VERSION ""

NS_ :

BS_:

BU_: Vector__XXX ECM_MOTOR ECU_eClutch PUMP CCU
VAL_TABLE_ OverVoltage 3 "N/A" 2 "Invalid" 1 "Active" 0 "Not Active" ;
VAL_TABLE_ MotorMode 3 "N/A" 2 "Running" 1 "Starting" 0 "Stopped" ;
VAL_TABLE_ FailedStart 3 "N/A" 2 "Invalid" 1 "Active" 0 "Not Active" ;
VAL_TABLE_ InputParamOutOfRange 3 "N/A" 2 "Invalid" 1 "Active" 0 "Not Active" ;
VAL_TABLE_ CurrentLimiting 3 "N/A" 2 "Invalid" 1 "Active" 0 "Not Active" ;
VAL_TABLE_ OverCurrent 3 "N/A" 2 "Invalid" 1 "Active" 0 "Not Active" ;
VAL_TABLE_ LowVoltage_MaxPWM 3 "N/A" 2 "Invalid" 1 "Active" 0 "Not Active" ;
VAL_TABLE_ Ramp 3 "Ramp #3" 2 "Ramp #2" 1 "Ramp #1" 0 "Ramp #0" ;
VAL_TABLE_ CommandStatus 62 "Fault" 20 "Stopped" 9 "Starting" 1 "Running" ;
VAL_TABLE_ ModeStatus 3 "Not Available" ;
VAL_TABLE_ Mode 3 "Not Available" 2 "Error" 1 "24V" 0 "12V" ;
VAL_TABLE_ Command 19 "Shutdown" 1 "Run" ;
VAL_TABLE_ CurrentLimit 255 "N/A" 254 "N/A" 253 "N/A" 252 "N/A" 251 "N/A" 250 "Limit to 12A" 249 "Limit to 12A" 248 "Limit to 12A" 247 "Limit to 12A" 246 "Limit to 12A" 245 "Limit to 12A" 244 "Limit to 12A" 243 "Limit to 12A" 242 "Limit to 12A" 241 "Limit to 12A" 240 "Limit to 12A" 239 "Limit to 12A" 238 "Limit to 12A" 237 "Limit to 12A" 236 "Limit to 12A" 235 "Limit to 12A" 234 "Limit to 12A" 233 "Limit to 12A" 232 "Limit to 12A" 231 "Limit to 12A" 230 "Limit to 12A" 229 "Limit to 12A" 228 "Limit to 12A" 227 "Limit to 12A" 226 "Limit to 12A" 225 "Limit to 12A" 224 "Limit to 12A" 223 "Limit to 12A" 222 "Limit to 12A" 221 "Limit to 12A" 220 "Limit to 12A" 219 "Limit to 12A" 218 "Limit to 12A" 217 "Limit to 12A" 216 "Limit to 12A" 215 "Limit to 12A" 214 "Limit to 12A" 213 "Limit to 12A" 212 "Limit to 12A" 211 "Limit to 12A" 210 "Limit to 12A" 209 "Limit to 12A" 208 "Limit to 12A" 207 "Limit to 12A" 206 "Limit to 12A" 205 "Limit to 12A" 204 "Limit to 12A" 203 "Limit to 12A" 202 "Limit to 12A" 201 "Limit to 12A" 200 "Limit to 12A" 199 "Limit to 12A" 198 "Limit to 12A" 197 "Limit to 12A" 196 "Limit to 12A" 195 "Limit to 12A" 194 "Limit to 12A" 193 "Limit to 12A" 192 "Limit to 12A" 191 "Limit to 12A" 190 "Limit to 12A" 189 "Limit to 12A" 188 "Limit to 12A" 187 "Limit to 12A" 186 "Limit to 12A" 185 "Limit to 12A" 184 "Limit to 12A" 183 "Limit to 12A" 182 "Limit to 12A" 181 "Limit to 12A" 180 "Limit to 12A" 179 "Limit to 12A" 178 "Limit to 12A" 177 "Limit to 12A" 176 "Limit to 12A" 175 "Limit to 12A" 174 "Limit to 12A" 173 "Limit to 12A" 172 "Limit to 12A" 171 "Limit to 12A" 170 "Limit to 12A" 169 "Limit to 12A" 168 "Limit to 12A" 167 "Limit to 12A" 166 "Limit to 12A" 165 "Limit to 12A" 164 "Limit to 12A" 163 "Limit to 12A" 162 "Limit to 12A" 161 "Limit to 12A" 160 "Limit to 12A" 159 "Limit to 12A" 158 "Limit to 12A" 157 "Limit to 12A" 156 "Limit to 12A" 155 "Limit to 12A" 154 "Limit to 12A" 153 "Limit to 12A" 152 "Limit to 12A" 151 "Limit to 12A" 150 "Limit to 12A" 149 "Limit to 12A" 148 "Limit to 12A" 147 "Limit to 12A" 146 "Limit to 12A" 145 "Limit to 12A" 144 "Limit to 12A" 143 "Limit to 12A" 142 "Limit to 12A" 141 "Limit to 12A" 140 "Limit to 12A" 139 "Limit to 12A" 138 "Limit to 12A" 137 "Limit to 12A" 136 "Limit to 12A" 135 "Limit to 12A" 134 "Limit to 12A" 133 "Limit to 12A" 132 "Limit to 12A" 131 "Limit to 12A" 130 "Limit to 12A" 129 "Limit to 12A" 128 "Limit to 12A" 127 "Limit to 12A" 126 "Limit to 12A" 125 "Limit to 12A" 124 "Limit to 12A" 123 "Limit to 12A" 122 "Limit to 12A" 121 "Limit to 12A" 120 "Limit to 12A" 119 "Limit to 12A" 118 "Limit to 12A" 117 "Limit to 12A" 116 "Limit to 12A" 115 "Limit to 12A" 114 "Limit to 12A" 113 "Limit to 12A" 112 "Limit to 12A" 111 "Limit to 12A" 110 "Limit to 12A" 109 "Limit to 12A" 108 "Limit to 12A" 107 "Limit to 12A" 106 "Limit to 12A" 105 "Limit to 12A" 104 "Limit to 12A" 103 "Limit to 12A" 102 "Limit to 12A" 101 "Limit to 12A" 100 "Limit to 12A" 99 "Limit to 12A" 98 "Limit to 12A" 97 "Limit to 12A" 96 "Limit to 12A" 95 "Limit to 12A" 94 "Limit to 12A" 93 "Limit to 12A" 92 "Limit to 12A" 91 "Limit to 12A" 90 "Limit to 12A" 89 "Limit to 12A" 88 "Limit to 12A" 87 "Limit to 12A" 86 "Limit to 12A" 85 "Limit to 12A" 84 "Limit to 12A" 83 "Limit to 12A" 82 "Limit to 12A" 81 "Limit to 12A" 80 "Limit to 12A" 79 "Limit to 12A" 78 "Limit to 12A" 77 "Limit to 12A" 76 "Limit to 12A" 75 "Limit to 12A" 74 "Limit to 12A" 73 "Limit to 12A" 72 "Limit to 12A" 71 "Limit to 12A" 70 "Limit to 12A" 69 "Limit to 12A" 68 "Limit to 12A" 67 "Limit to 12A" 66 "Limit to 12A" 65 "Limit to 12A" 64 "Limit to 12A" 63 "Limit to 12A" 62 "Limit to 12A" 61 "Limit to 12A" 60 "Limit to 12A" 59 "Limit to 12A" 58 "Limit to 12A" 57 "Limit to 12A" 56 "Limit to 12A" 55 "Limit to 12A" 54 "Limit to 12A" 53 "Limit to 12A" 52 "Limit to 12A" 51 "Limit to 12A" 50 "Limit to 12A" 49 "Limit to 12A" 48 "Limit to 12A" 47 "Limit to 12A" 46 "Limit to 12A" 45 "Limit to 12A" 44 "Limit to 12A" 43 "Limit to 12A" 42 "Limit to 12A" 41 "Limit to 12A" 40 "Limit to 12A" 39 "Limit to 12A" 38 "Limit to 12A" 37 "Limit to 12A" 36 "Limit to 12A" 35 "Limit to 12A" 34 "Limit to 12A" 33 "Limit to 12A" 32 "Limit to 12A" 31 "Limit to 12A" 30 "Limit to 12A" 29 "Limit to 12A" 28 "Limit to 12A" 27 "Limit to 12A" 26 "Limit to 12A" 25 "Limit to 12A" 24 "Limit to 12A" 23 "Limit to 12A" 22 "Limit to 12A" 21 "Limit to 12A" 20 "Limit to 12A" 19 "Limit to 12A" 18 "Limit to 12A" 17 "Limit to 12A" 16 "Limit to 12A" 15 "Limit to 12A" 14 "Limit to 12A" 13 "Limit to 12A" 12 "Limit to 12A" 11 "Limit to 11A" 10 "Limit to 10 A" 9 "Limit to 9 A" 8 "Limit to 8 A" 7 "Limit to 7 A" 6 "Limit to 6 A" 5 "Limit to 5 A" 4 "Limit to 4 A" 3 "Limit to 3 A" 2 "Limit to 2 A" 1 "Limit to 1 A" 0 "Limit to 7 A" ;

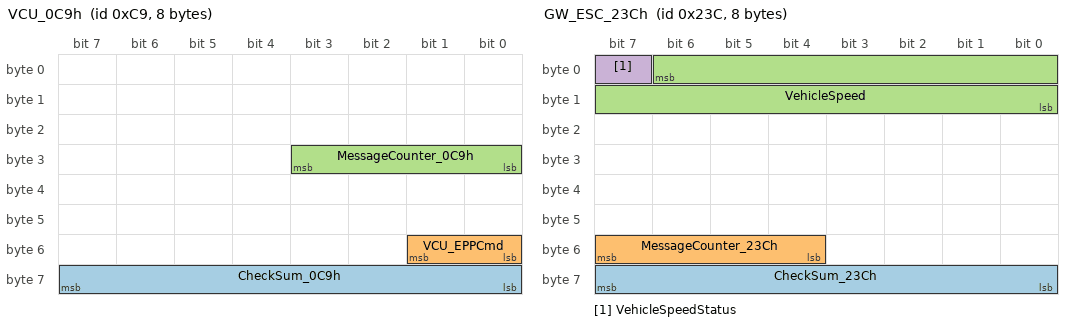
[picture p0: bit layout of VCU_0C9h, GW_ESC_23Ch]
BO_ 201 VCU_0C9h: 8 Vector__XXX
 SG_ CheckSum_0C9h : 63|8@0+ (1,0) [0|255] "" Vector__XXX
 SG_ VCU_EPPCmd : 49|2@0+ (1,0) [0|1] "" Vector__XXX
 SG_ MessageCounter_0C9h : 27|4@0+ (1,0) [0|15] "" Vector__XXX

BO_ 572 GW_ESC_23Ch: 8 Vector__XXX
 SG_ CheckSum_23Ch : 63|8@0+ (1,0) [0|255] "" Vector__XXX
 SG_ MessageCounter_23Ch : 55|4@0+ (1,0) [0|15] "" Vector__XXX
 SG_ VehicleSpeed : 6|15@0+ (0.015625,0) [0|511.984375] "km / h" Vector__XXX
 SG_ VehicleSpeedStatus : 7|1@0+ (1,0) [0|1] "" Vector__XXX

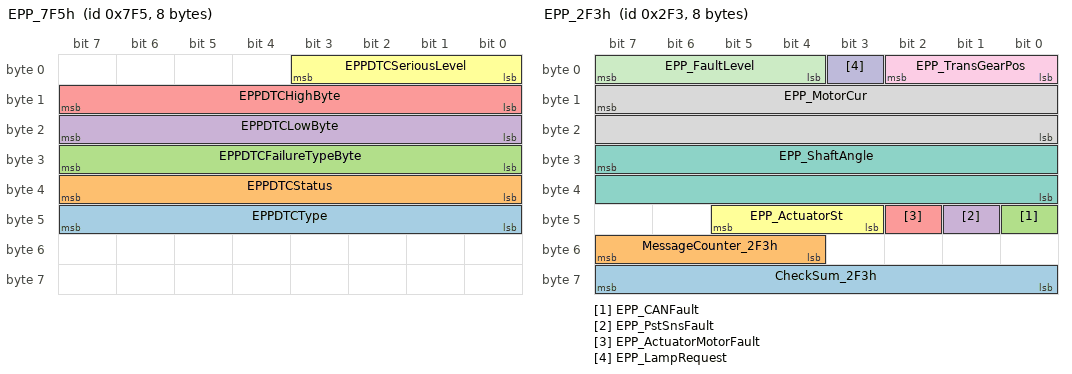
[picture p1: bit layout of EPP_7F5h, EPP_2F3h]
BO_ 2037 EPP_7F5h: 8 Vector__XXX
 SG_ EPPDTCType : 47|8@0+ (1,0) [0|255] "" Vector__XXX
 SG_ EPPDTCStatus : 39|8@0+ (1,0) [0|255] "" Vector__XXX
 SG_ EPPDTCFailureTypeByte : 31|8@0+ (1,0) [0|255] "" Vector__XXX
 SG_ EPPDTCLowByte : 23|8@0+ (1,0) [0|255] "" Vector__XXX
 SG_ EPPDTCHighByte : 15|8@0+ (1,0) [0|255] "" Vector__XXX
 SG_ EPPDTCSeriousLevel : 3|4@0+ (1,0) [0|15] "" Vector__XXX

BO_ 755 EPP_2F3h: 8 Vector__XXX
 SG_ CheckSum_2F3h : 63|8@0+ (1,0) [0|255] "" Vector__XXX
 SG_ MessageCounter_2F3h : 55|4@0+ (1,0) [0|15] "" Vector__XXX
 SG_ EPP_CANFault : 40|1@0+ (1,0) [0|1] "" Vector__XXX
 SG_ EPP_PstSnsFault : 41|1@0+ (1,0) [0|1] "" Vector__XXX
 SG_ EPP_ActuatorMotorFault : 42|1@0+ (1,0) [0|1] "" Vector__XXX
 SG_ EPP_ActuatorSt : 45|3@0+ (1,0) [0|7] "" Vector__XXX
 SG_ EPP_ShaftAngle : 31|16@0+ (0.0030517578125,-100) [-100|99.9969482421875] "Deg" Vector__XXX
 SG_ EPP_MotorCur : 15|16@0+ (0.0030517578125,-100) [-100|99.9969482421875] "A" Vector__XXX
 SG_ EPP_TransGearPos : 2|3@0+ (1,0) [0|7] "" Vector__XXX
 SG_ EPP_LampRequest : 3|1@0+ (1,0) [0|1] "" Vector__XXX
 SG_ EPP_FaultLevel : 7|4@0+ (1,0) [0|15] "" Vector__XXX

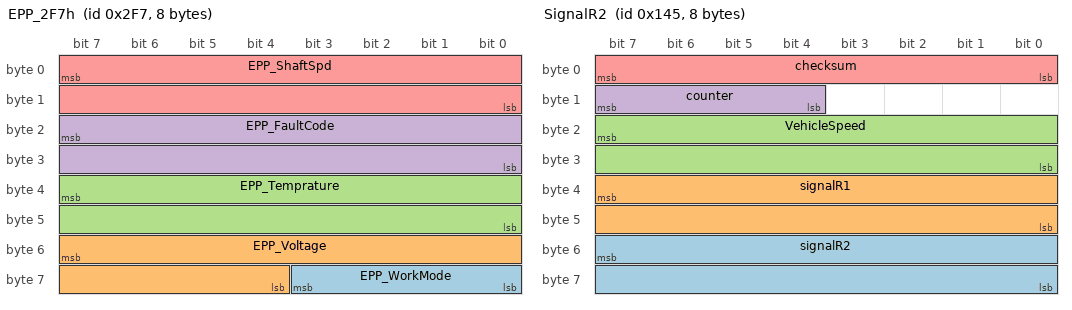
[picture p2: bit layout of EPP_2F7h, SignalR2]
BO_ 759 EPP_2F7h: 8 Vector__XXX
 SG_ EPP_WorkMode : 59|4@0+ (1,0) [0|15] "" Vector__XXX
 SG_ EPP_Voltage : 55|12@0+ (0.0103759765625,0) [0|42.4896] "V" Vector__XXX
 SG_ EPP_Temprature : 39|16@0+ (0.0030517578125,-45) [-45|154.9969] "℃" Vector__XXX
 SG_ EPP_FaultCode : 23|16@0+ (1,0) [0|4095] "" Vector__XXX
 SG_ EPP_ShaftSpd : 7|16@0+ (0.0030517578125,-100) [-100|99.9969482421875] "rpm" Vector__XXX

BO_ 325 SignalR2: 8 ECU_eClutch
 SG_ signalR2 : 55|16@0+ (1,0) [0|65535] ""  ECM_MOTOR
 SG_ signalR1 : 39|16@0+ (1,0) [0|65535] ""  ECM_MOTOR
 SG_ VehicleSpeed : 23|16@0+ (0.015625,0) [0|1023.984375] "km/h"  ECM_MOTOR
 SG_ counter : 15|4@0+ (1,0) [0|15] ""  ECM_MOTOR
 SG_ checksum : 7|8@0+ (1,0) [0|255] ""  ECM_MOTOR

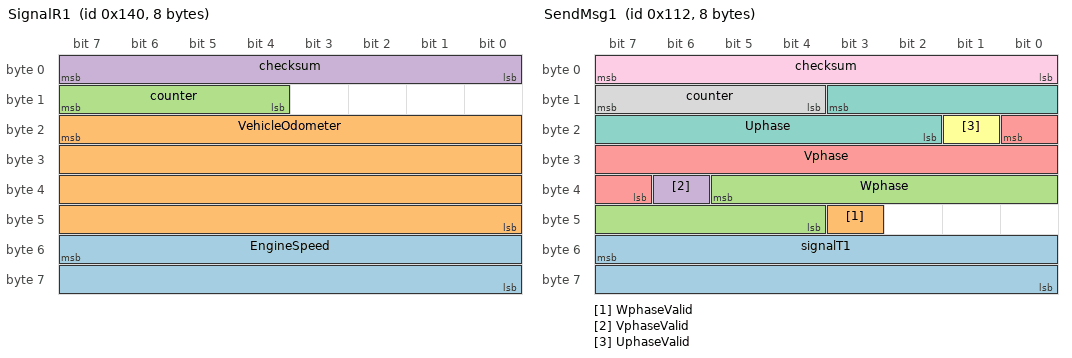
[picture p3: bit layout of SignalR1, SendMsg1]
BO_ 320 SignalR1: 8 ECU_eClutch
 SG_ EngineSpeed : 55|16@0+ (0.25,0) [0|16383.75] "rpm"  ECM_MOTOR
 SG_ VehicleOdometer : 23|32@0+ (0.015625,0) [0|67108863.984375] "km"  ECM_MOTOR
 SG_ counter : 15|4@0+ (1,0) [0|15] ""  ECM_MOTOR
 SG_ checksum : 7|8@0+ (1,0) [0|255] ""  ECM_MOTOR

BO_ 274 SendMsg1: 8 ECM_MOTOR
 SG_ signalT1 : 55|16@0+ (1,0) [0|65535] ""  ECU_eClutch
 SG_ WphaseValid : 43|1@0+ (1,0) [0|1] ""  ECU_eClutch
 SG_ Wphase : 37|10@0+ (0.195,-100) [-100|99.485] ""  ECU_eClutch
 SG_ VphaseValid : 38|1@0+ (1,0) [0|1] ""  ECU_eClutch
 SG_ Vphase : 16|10@0+ (0.195,-100) [-100|99.485] ""  ECU_eClutch
 SG_ UphaseValid : 17|1@0+ (1,0) [0|1] ""  ECU_eClutch
 SG_ Uphase : 11|10@0+ (0.195,-100) [-100|99.485] ""  ECU_eClutch
 SG_ counter : 15|4@0+ (1,0) [0|15] ""  ECU_eClutch
 SG_ checksum : 7|8@0+ (1,0) [0|255] ""  ECU_eClutch

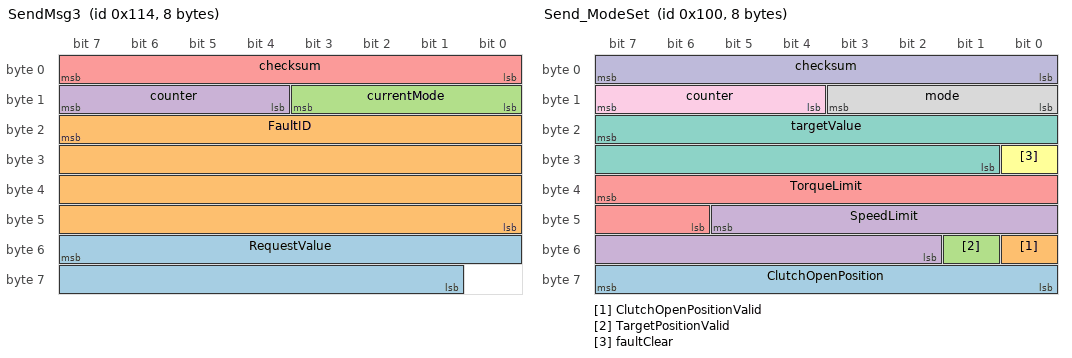
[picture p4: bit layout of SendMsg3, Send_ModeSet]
BO_ 276 SendMsg3: 8 ECM_MOTOR
 SG_ RequestValue : 55|15@0+ (1,0) [0|32767] ""  ECU_eClutch
 SG_ FaultID : 23|32@0+ (1,0) [0|4294967295] ""  ECU_eClutch
 SG_ currentMode : 11|4@0+ (1,0) [0|15] ""  ECU_eClutch
 SG_ counter : 15|4@0+ (1,0) [0|15] ""  ECU_eClutch
 SG_ checksum : 7|8@0+ (1,0) [0|255] ""  ECU_eClutch

BO_ 256 Send_ModeSet: 8 ECU_eClutch
 SG_ ClutchOpenPosition : 63|8@0+ (0.1,0) [0|25.5] "rev"  ECM_MOTOR
 SG_ ClutchOpenPositionValid : 48|1@0+ (1,0) [0|1] ""  ECM_MOTOR
 SG_ TargetPositionValid : 49|1@0+ (1,0) [0|1] ""  ECM_MOTOR
 SG_ SpeedLimit : 45|12@0+ (2.442,0) [0|9999.99] ""  ECM_MOTOR
 SG_ TorqueLimit : 39|10@0+ (0.0977,0) [0|99.9471] ""  ECM_MOTOR
 SG_ faultClear : 24|1@0+ (1,0) [0|1] ""  ECM_MOTOR
 SG_ targetValue : 23|15@0+ (1,0) [0|32767] ""  ECM_MOTOR
 SG_ mode : 11|4@0+ (1,0) [0|15] ""  ECM_MOTOR
 SG_ counter : 15|4@0+ (1,0) [0|15] ""  ECM_MOTOR
 SG_ checksum : 7|8@0+ (1,0) [0|255] ""  ECM_MOTOR

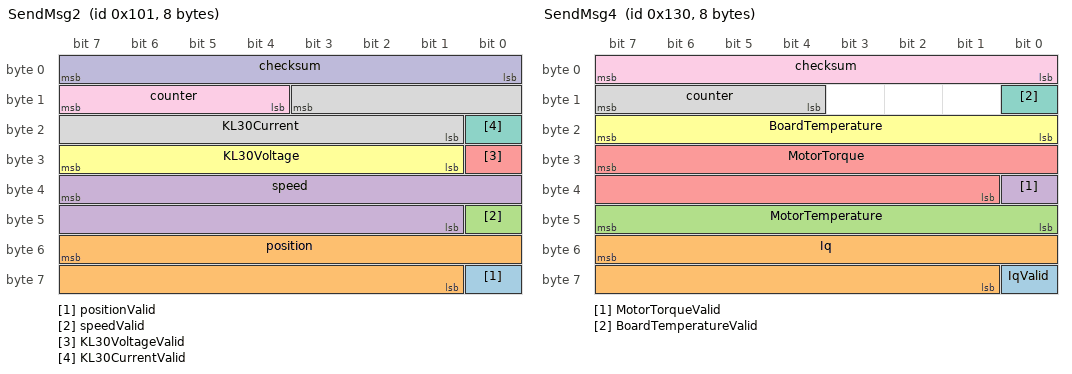
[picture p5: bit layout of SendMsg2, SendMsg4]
BO_ 257 SendMsg2: 8 ECM_MOTOR
 SG_ positionValid : 56|1@0+ (1,0) [0|1] ""  ECU_eClutch
 SG_ position : 55|15@0+ (0.001526,-25) [-25|25.002442] ""  ECU_eClutch
 SG_ speedValid : 40|1@0+ (1,0) [0|1] ""  ECU_eClutch
 SG_ speed : 39|15@0+ (0.6104,-10000) [-10000|10000.9768] ""  ECU_eClutch
 SG_ KL30VoltageValid : 24|1@0+ (1,0) [0|1] ""  ECU_eClutch
 SG_ KL30Voltage : 31|7@0+ (0.237,0) [0|30.099] ""  ECU_eClutch
 SG_ KL30CurrentValid : 16|1@0+ (1,0) [0|1] ""  ECU_eClutch
 SG_ KL30Current : 11|11@0+ (0.0489,0) [0|100.0983] ""  ECU_eClutch
 SG_ counter : 15|4@0+ (1,0) [0|15] ""  ECU_eClutch
 SG_ checksum : 7|8@0+ (1,0) [0|255] ""  ECU_eClutch

BO_ 304 SendMsg4: 8 ECM_MOTOR
 SG_ IqValid : 56|1@0+ (1,0) [0|1] ""  ECU_eClutch
 SG_ Iq : 55|15@0+ (0.01,-160) [-160|167.67] ""  ECU_eClutch
 SG_ MotorTemperature : 47|8@0+ (1,-60) [-60|195] ""  ECU_eClutch
 SG_ MotorTorqueValid : 32|1@0+ (1,0) [0|1] ""  ECU_eClutch
 SG_ MotorTorque : 31|15@0+ (0.0001525,-2) [-2|2.9969675] ""  ECU_eClutch
 SG_ BoardTemperature : 23|8@0+ (1,-60) [-60|195] ""  ECU_eClutch
 SG_ BoardTemperatureValid : 8|1@0+ (1,0) [0|1] ""  ECU_eClutch
 SG_ counter : 15|4@0+ (1,0) [0|15] ""  ECU_eClutch
 SG_ checksum : 7|8@0+ (1,0) [0|255] ""  ECU_eClutch

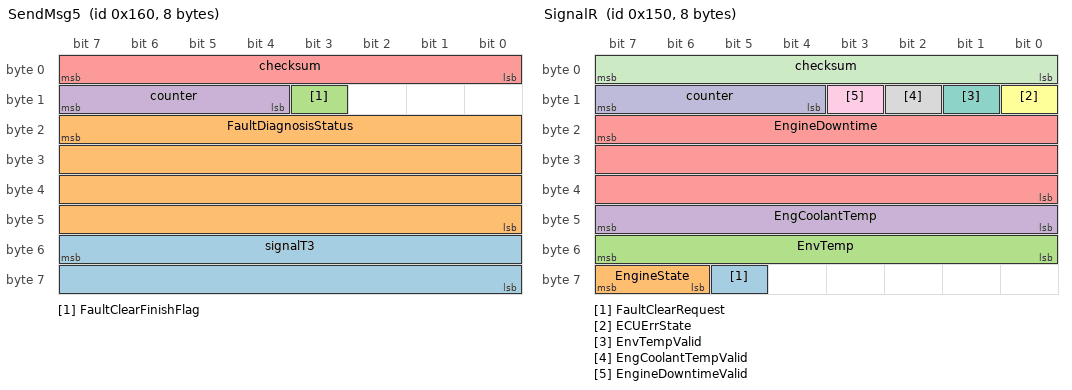
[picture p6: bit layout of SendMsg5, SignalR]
BO_ 352 SendMsg5: 8 ECM_MOTOR
 SG_ signalT3 : 55|16@0+ (1,0) [0|65535] ""  ECU_eClutch
 SG_ FaultDiagnosisStatus : 23|32@0+ (1,0) [0|4294967295] ""  ECU_eClutch
 SG_ FaultClearFinishFlag : 11|1@0+ (1,0) [0|1] ""  ECU_eClutch
 SG_ counter : 15|4@0+ (1,0) [0|15] ""  ECU_eClutch
 SG_ checksum : 7|8@0+ (1,0) [0|255] ""  ECU_eClutch

BO_ 336 SignalR: 8 ECU_eClutch
 SG_ FaultClearRequest : 61|1@0+ (1,0) [0|1] ""  ECM_MOTOR
 SG_ EngineState : 63|2@0+ (1,0) [0|3] ""  ECM_MOTOR
 SG_ EnvTemp : 55|8@0+ (1,-40) [-40|215] "℃"  ECM_MOTOR
 SG_ EngCoolantTemp : 47|8@0+ (1,-40) [-40|215] "℃"  ECM_MOTOR
 SG_ EngineDowntime : 23|24@0+ (1,0) [0|16777215] "s"  ECM_MOTOR
 SG_ ECUErrState : 8|1@0+ (1,0) [0|1] ""  ECM_MOTOR
 SG_ EnvTempValid : 9|1@0+ (1,0) [0|1] ""  ECM_MOTOR
 SG_ EngCoolantTempValid : 10|1@0+ (1,0) [0|1] ""  ECM_MOTOR
 SG_ EngineDowntimeValid : 11|1@0+ (1,0) [0|1] ""  ECM_MOTOR
 SG_ counter : 15|4@0+ (1,0) [0|15] ""  ECM_MOTOR
 SG_ checksum : 7|8@0+ (1,0) [0|255] ""  ECM_MOTOR

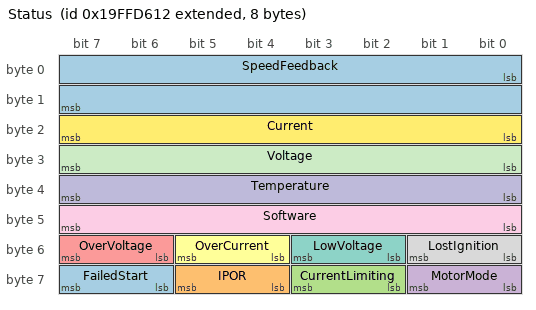
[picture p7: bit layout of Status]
BO_ 2583680530 Status: 8 PUMP
 SG_ FailedStart : 62|2@1+ (1,0) [0|3] ""  CCU
 SG_ IPOR : 60|2@1+ (1,0) [0|3] ""  CCU
 SG_ CurrentLimiting : 58|2@1+ (1,0) [0|3] ""  CCU
 SG_ MotorMode : 56|2@1+ (1,0) [0|3] ""  CCU
 SG_ OverVoltage : 54|2@1+ (1,0) [0|3] ""  CCU
 SG_ OverCurrent : 52|2@1+ (1,0) [0|3] ""  CCU
 SG_ LowVoltage : 50|2@1+ (1,0) [0|3] ""  CCU
 SG_ LostIgnition : 48|2@1+ (1,0) [0|3] ""  CCU
 SG_ Software : 40|8@1+ (1,0) [0|255] "Rev"  CCU
 SG_ Temperature : 32|8@1+ (1,-40) [-40|210] "DegC"  CCU
 SG_ Voltage : 24|8@1+ (0.2,0) [0|50] "V"  CCU
 SG_ Current : 16|8@1+ (0.05,0) [0|12.5] "A"  CCU
 SG_ SpeedFeedback : 0|16@1+ (1,-32127) [-32127|32128] "RPM"  CCU

BO_ 2382353408 Command: 8 CCU
 SG_ RunCommand : 16|8@1+ (1,0) [0|255] ""  PUMP
 SG_ SpeedCommand : 0|16@1+ (1,-32127) [-32127|32128] "RPM"  PUMP

CM_ SG_ 201 CheckSum_0C9h "CheckSum=Byet(0) XOR Byte(1) XOR Byte(2) XOR Byte(3) XOR Byte(4) XOR Byte(5) XOR Byte(6) ";
CM_ SG_ 201 VCU_EPPCmd "VCU request EPP ";
CM_ SG_ 201 MessageCounter_0C9h " ";
CM_ SG_ 572 CheckSum_23Ch "Checksum=byte(0) XOR byte(1) XOR byte(2) XOR byte(3) XOR byte(4) XOR byte(5) XOR byte(6)  ";
CM_ SG_ 572 MessageCounter_23Ch "  ";
CM_ SG_ 572 VehicleSpeed " ";
CM_ SG_ 572 VehicleSpeedStatus " ";
CM_ SG_ 2037 EPPDTCType "  ";
CM_ SG_ 2037 EPPDTCStatus "  ";
CM_ SG_ 2037 EPPDTCFailureTypeByte "  ";
CM_ SG_ 2037 EPPDTCLowByte "  ";
CM_ SG_ 2037 EPPDTCHighByte "  ";
CM_ SG_ 2037 EPPDTCSeriousLevel "  ";
CM_ SG_ 755 CheckSum_2F3h "Checksum=byte(0) XOR byte(1) XOR byte(2) XOR byte(3) XOR byte(4) XOR byte(5) XOR byte(6)  ";
CM_ SG_ 755 MessageCounter_2F3h "  ";
CM_ SG_ 755 EPP_CANFault "CAN receive detection only for the Message which transfer main request ";
CM_ SG_ 755 EPP_PstSnsFault "Sensor fault or unpluged ";
CM_ SG_ 755 EPP_ActuatorMotorFault "Motor fault or unpluged ";
CM_ SG_ 755 EPP_ActuatorSt "System status ";
CM_ SG_ 755 EPP_ShaftAngle "EPP output shaft angle ";
CM_ SG_ 755 EPP_MotorCur "EPP motor current ";
CM_ SG_ 755 EPP_TransGearPos "Indicating the transmission gear position ";
CM_ SG_ 755 EPP_LampRequest "Active in case of E_Park system fault occurred, reuqest for light up the diagnostic lamp on ICM.(Optional) ";
CM_ SG_ 755 EPP_FaultLevel "EPP Fault level ";
CM_ BO_ 759 "仅PP前使用";
CM_ SG_ 759 EPP_WorkMode " ";
CM_ SG_ 759 EPP_Voltage " ";
CM_ SG_ 759 EPP_Temprature " ";
CM_ SG_ 759 EPP_FaultCode " ";
CM_ SG_ 759 EPP_ShaftSpd " ";
BA_DEF_  "BusType" STRING ;
BA_DEF_ BO_  "GenMsgCycleTime" INT 0 65535;
BA_DEF_ SG_  "GenSigStartValue" FLOAT -3.4E+38 3.4E+38;
BA_DEF_ SG_  "SigType" ENUM  "Default","Range","RangeSigned","ASCII","Discrete","Control","ReferencePGN","DTC","StringDelimiter","StringLength","StringLengthControl";
BA_DEF_ SG_  "GenSigEVName" STRING ;
BA_DEF_ SG_  "GenSigILSupport" ENUM  "No","Yes";
BA_DEF_ SG_  "GenSigSendType" ENUM  "Cyclic","OnWrite","OnWriteWithRepetition","OnChange","OnChangeWithRepetition","IfActive","IfActiveWithRepetition","NoSigSendType";
BA_DEF_ BO_  "GenMsgILSupport" ENUM  "No","Yes";
BA_DEF_ BU_  "NmStationAddress" INT 0 255;
BA_DEF_ BO_  "GenMsgSendType" ENUM  "cyclic","NotUsed","IfActive","NotUsed","NotUsed","NotUsed","NotUsed","NotUsed","noMsgSendType";
BA_DEF_ BO_  "GenMsgRequestable" INT 0 1;
BA_DEF_ SG_  "SPN" INT 0 524287;
BA_DEF_  "DBName" STRING ;
BA_DEF_  "ProtocolType" STRING ;
BA_DEF_ BO_  "VFrameFormat" ENUM  "StandardCAN","ExtendedCAN","reserved","J1939PG";
BA_DEF_DEF_  "BusType" "CAN";
BA_DEF_DEF_  "GenMsgCycleTime" 0;
BA_DEF_DEF_  "GenSigStartValue" 0;
BA_DEF_DEF_  "SigType" "Default";
BA_DEF_DEF_  "GenSigEVName" "Env@Nodename_@Signame";
BA_DEF_DEF_  "GenSigILSupport" "Yes";
BA_DEF_DEF_  "GenSigSendType" "NoSigSendType";
BA_DEF_DEF_  "GenMsgILSupport" "Yes";
BA_DEF_DEF_  "NmStationAddress" 254;
BA_DEF_DEF_  "GenMsgSendType" "noMsgSendType";
BA_DEF_DEF_  "GenMsgRequestable" 1;
BA_DEF_DEF_  "SPN" 0;
BA_DEF_DEF_  "DBName" "";
BA_DEF_DEF_  "ProtocolType" "J1939";
BA_DEF_DEF_  "VFrameFormat" "J1939PG";
BA_ "DBName" "Project_Spinnaker_D4_12";
BA_ "NmStationAddress" BU_ PUMP 18;
BA_ "NmStationAddress" BU_ CCU 0;
BA_ "GenMsgCycleTime" BO_ 201 10;
BA_ "GenMsgCycleTime" BO_ 572 20;
BA_ "GenMsgCycleTime" BO_ 755 20;
BA_ "GenMsgCycleTime" BO_ 759 20;
BA_ "GenMsgCycleTime" BO_ 325 10;
BA_ "GenMsgCycleTime" BO_ 320 10;
BA_ "GenMsgCycleTime" BO_ 274 10;
BA_ "GenSigStartValue" SG_ 274 Wphase 512.820512820513;
BA_ "GenSigStartValue" SG_ 274 Vphase 512.820512820513;
BA_ "GenSigStartValue" SG_ 274 Uphase 512.820512820513;
BA_ "GenMsgCycleTime" BO_ 276 10;
BA_ "GenMsgCycleTime" BO_ 256 10;
BA_ "GenMsgCycleTime" BO_ 257 10;
BA_ "GenSigStartValue" SG_ 257 position 16382.6998689384;
BA_ "GenSigStartValue" SG_ 257 speed 16382.6998689384;
BA_ "GenMsgCycleTime" BO_ 304 10;
BA_ "GenSigStartValue" SG_ 304 Iq 16000;
BA_ "GenSigStartValue" SG_ 304 MotorTemperature 60;
BA_ "GenSigStartValue" SG_ 304 MotorTorque 13114.7540983607;
BA_ "GenSigStartValue" SG_ 304 BoardTemperature 60;
BA_ "GenMsgCycleTime" BO_ 352 10;
BA_ "GenMsgCycleTime" BO_ 336 10;
BA_ "GenSigStartValue" SG_ 336 EnvTemp 40;
BA_ "GenSigStartValue" SG_ 336 EngCoolantTemp 40;
BA_ "GenMsgCycleTime" BO_ 2382353408 20;
BA_ "GenMsgSendType" BO_ 2382353408 0;
VAL_ 201 VCU_EPPCmd 0 "Disable(VCU不使能EPP)" 1 "Lock(VCU发驻车指令)" 2 "Unlock(VCU发解锁指令)" 3 "Shut Down(VCU发休眠令)" ;
VAL_ 572 VehicleSpeedStatus 1 "Invalid" 0 "Valid" ;
VAL_ 2037 EPPDTCType 7 "Reserved" 6 "Type F" 5 "Type E" 4 "Type D" 3 "Type C" 2 "Type B" 1 "Type A" 0 "Not Used" ;
VAL_ 2037 EPPDTCSeriousLevel 15 "Reserved" 14 "Reserved" 13 "Reserved" 12 "Reserved" 11 "Reserved" 10 "Reserved" 9 "Reserved" 8 "Reserved" 7 "Reserved" 6 "Reserved" 5 "Reserved" 4 "Level Ⅳ" 3 "Level Ⅲ" 2 "Level Ⅱ" 1 "Level Ⅰ" 0 "Not Used" ;
VAL_ 755 EPP_CANFault 0 "No Fault" 1 "Fault" ;
VAL_ 755 EPP_PstSnsFault 0 "No Fault" 1 "Fault" ;
VAL_ 755 EPP_ActuatorMotorFault 0 "No Fault" 1 "Fault" ;
VAL_ 755 EPP_ActuatorSt 0 "Inital" 1 "Reserved" 2 "Locked" 3 "Reserved" 4 "Reserved" 5 "Unlocked" 6 "Reserved" 7 "Unknown" ;
VAL_ 755 EPP_TransGearPos 0 "Not initialized" 1 "Unknown（角度传感器有故障）" 2 "Park" 3 "Park stall" 4 "Between Park and UnPark" 5 "UnPark" 6 "UnPark stall" 7 "Reserved" ;
VAL_ 755 EPP_LampRequest 1 "Request" 0 "No Request" ;
VAL_ 755 EPP_FaultLevel 0 "no fault" 1 "Failure level 1" 2 "Failure level 2" 3 "3-15Reserved" ;
VAL_ 759 EPP_WorkMode 0 "Idle H桥不使能" 1 "Standby H桥处于刹车模式" 2 "Duty TPL为占空比控制模式" 3 "Current TPL为电流控制模式" 4 "SpeedTPL为转速控制模式" 5 "Position TPL为位置控制模式" 6 "SelfLearn TPL为自学习模式" ;
VAL_ 276 currentMode 0 "AppPowerStageOffMode" 2 "AppTorqueMode" 3 "AppSpeedMode" 4 "AppPositionMode" 1 "AppSpecialControlMode" 5 "AppShutdownMode" ;
VAL_ 256 mode 0 "AppPowerStageOffMode" 2 "AppTorqueMode" 3 "AppSpeedMode" 4 "AppPositionMode" 1 "AppSpecialControlMode" 5 "AppShutdownMode" ;
VAL_ 2583680530 FailedStart 3 "N/A" 2 "Invalid" 1 "Active" 0 "Not Active" ;
VAL_ 2583680530 IPOR 3 "N/A" 2 "Invalid" 1 "Active" 0 "Not Active" ;
VAL_ 2583680530 CurrentLimiting 3 "N/A" 2 "Invalid" 1 "Active" 0 "Not Active" ;
VAL_ 2583680530 MotorMode 3 "Low RPM Mode" 2 "N/A" 1 "Running" 0 "Stopped" ;
VAL_ 2583680530 OverVoltage 3 "N/A" 2 "Invalid" 1 "Active" 0 "Not Active" ;
VAL_ 2583680530 OverCurrent 3 "N/A" 2 "Invalid" 1 "Active" 0 "Not Active" ;
VAL_ 2583680530 LowVoltage 3 "N/A" 2 "Invalid" 1 "Active" 0 "Not Active" ;
VAL_ 2583680530 LostIgnition 3 "N/A" 2 "Invalid" 1 "Active" 0 "Not Active" ;
VAL_ 2382353408 RunCommand 211 "Stop" 193 "Run" ;
